# EMU_CM register map
Vendor: Texas Instruments
Peripheral module from a debugger description file (folder am572x).
Registers are 32-bit, access per field, reset 0x2 unless marked. A register's access mark holds for its fields unless they carry their own. Offsets are as the file gives them; lines under a group give offsets from that group; [hi:lo] are bit positions; {n}, {i} and the like mark numbered series; 'fields as' and 'values as' point back to an identical list; <NAME> marks a mode.

## EMU_CM
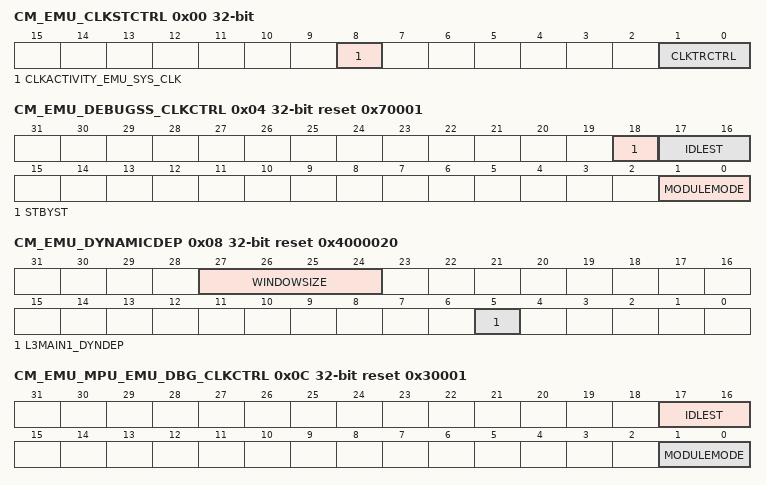
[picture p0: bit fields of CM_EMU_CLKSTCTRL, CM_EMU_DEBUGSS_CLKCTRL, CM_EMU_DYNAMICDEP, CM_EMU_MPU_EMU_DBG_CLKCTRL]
0x00 CM_EMU_CLKSTCTRL — This register enables the EMU domain power state transition. It controls the HW supervised domain power state transition between ON-ACTIVE and ON-INACTIVE states. It also hold one status bit per clock input of the domain. [warm reset insensitive]
  [8] CLKACTIVITY_EMU_SYS_CLK ro — This field indicates the state of the EMU_SYS_CLK clock in the domain.
    0=INACT (Corresponding clock is definitely gated); 1=ACT (Corresponding clock is running or gating/ungating transition is on-going)
  [1:0] CLKTRCTRL rw — Controls the clock state transition of the EMU clock domain.
    2=SW_WKUP (SW_WKUP: Start a software forced wake-up transition on the domain.); 3=HW_AUTO (HW_AUTO: Automatic transition is enabled. Sleep and wakeup transition are based upon hardware conditions.)
0x04 CM_EMU_DEBUGSS_CLKCTRL ro reset 0x70001 — This register manages the DEBUGSS clocks. [warm reset insensitive]
  [18] STBYST — Module standby status
    0=FUNC (Module is functional (not in standby)); 1=STANDBY (Module is in standby)
  [17:16] IDLEST — Module idle status
    0=FUNC (Module is fully functional, including OCP); 1=TRANS (Module is performing transition: wakeup, or sleep, or sleep abortion); 2=IDLE (Module is in Idle mode (only OCP part). It is functional if using separate functional clock); 3=DISABLE (Module is disabled and cannot be accessed)
  [1:0] MODULEMODE — Control the way mandatory clocks are managed.
    1=AUTO (Module is managed automatically by HW according to clock domain transition. A clock domain sleep transition put module into idle. A wakeup domain transition put it back into function. If CLKTRCTRL=3, any OCP access to module is always granted. Module clocks may be gated according to the clock domain state.)
0x08 CM_EMU_DYNAMICDEP reset 0x4000020 — This register controls the dynamic domain depedencies from EMU domain towards 'target' domains. It is relevant only for domain having OCP master port(s).
  [27:24] WINDOWSIZE rw — Size of sliding window used to monitor OCP interface activity for determination of auto-sleep feature. Time unit defined byCM_DYN_DEP_PRESCAL register.
  [5] L3MAIN1_DYNDEP ro — Dynamic dependency towards L3MAIN1 clock domain
    1=ENABLED (Dependency is enabled)
0x0C CM_EMU_MPU_EMU_DBG_CLKCTRL ro reset 0x30001 — This register manages the MPU_EMU_DBG clocks. [warm reset insensitive]
  [17:16] IDLEST — Module idle status
    values as CM_EMU_DEBUGSS_CLKCTRL.IDLEST
  [1:0] MODULEMODE — Control the way mandatory clocks are managed.
    values as CM_EMU_DEBUGSS_CLKCTRL.MODULEMODE
